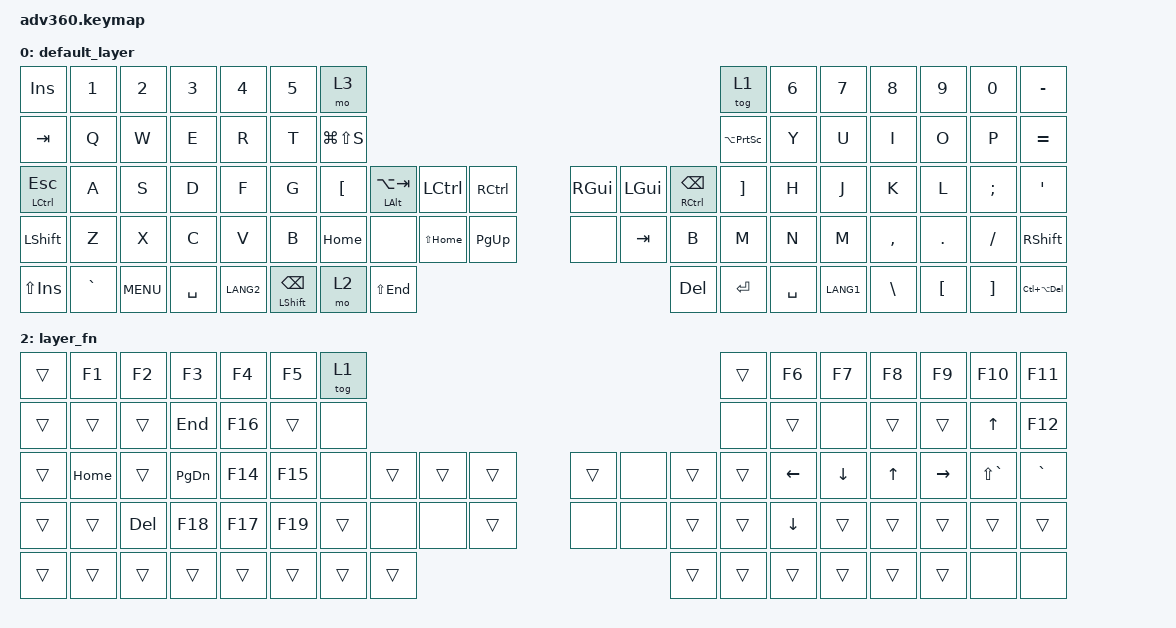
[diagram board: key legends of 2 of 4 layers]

/*
 * Copyright (c) 2020 The ZMK Contributors
 *
 * SPDX-License-Identifier: MIT
 */


/* THIS FILE WAS GENERATED!
 *
 * This file was generated automatically. You may or may not want to
 * edit it directly.
 */

#include <behaviors.dtsi>
#include <dt-bindings/zmk/keys.h>
#include <dt-bindings/zmk/bt.h>
#include <dt-bindings/zmk/rgb.h>
#include <dt-bindings/zmk/backlight.h>

/ {
  behaviors {
    #include "macros.dtsi"

    hm: homerow_mods {
        compatible = "zmk,behavior-hold-tap";
        label = "HOMEROW_MODS";
        #binding-cells = <2>;
        tapping-term-ms = <200>;
        quick_tap_ms = <175>;
        flavor = "tap-preferred";
        bindings = <&kp>, <&kp>;
    };
  };

    keymap {
        compatible = "zmk,keymap";


        default_layer {
            bindings = <
     &kp INSERT     &kp N1      &kp N2     &kp N3     &kp N4  &kp N5                          &mo 3                                                                                                  &tog 1  &kp N6     &kp N7         &kp N8    &kp N9    &kp N0        &kp MINUS
        &kp TAB      &kp Q       &kp W      &kp E      &kp R   &kp T                  &kp LG(LS(S))                                                                                     &kp LA(PRINTSCREEN)   &kp Y      &kp U          &kp I     &kp O     &kp P        &kp EQUAL
  &mt LCTRL ESC      &kp A       &kp S      &kp D      &kp F   &kp G                       &kp LBKT  &mt LEFT_ALT LA(TAB)     &kp LCTRL  &kp RCTRL  &kp RGUI  &kp LGUI  &mt RCTRL BSPC             &kp RBKT   &kp H      &kp J          &kp K     &kp L  &kp SEMI          &kp SQT
      &kp LSHFT      &kp Z       &kp X      &kp C      &kp V   &kp B                       &kp HOME                 &none  &kp LS(HOME)  &kp PG_UP     &none   &kp TAB           &kp B                &kp M   &kp N      &kp M      &kp COMMA   &kp DOT  &kp FSLH        &kp RSHFT
 &kp LS(INSERT)  &kp GRAVE  &kp C_MENU  &kp SPACE  &kp LANG2                    &mt LEFT_SHIFT BSPC                 &mo 2   &kp LS(END)                        &kp DEL       &kp ENTER            &kp SPACE          &kp LANG1  &kp BACKSLASH  &kp LBKT  &kp RBKT  &kp LC(LA(DEL))
            >;
        };

        layer_keypad {
            bindings = <
 &kp EQUAL    &kp N1     &kp N2    &kp N3   &kp N4  &kp N5              &trans                                                                     &mo 3     &kp N6  &kp KP_NUM  &kp KP_EQUAL  &kp KP_DIVIDE  &kp KP_MULTIPLY  &kp MINUS
   &kp TAB     &kp Q      &kp W     &kp E    &kp R   &kp T               &none                                                                     &none      &kp Y   &kp KP_N7     &kp KP_N8      &kp KP_N9     &kp KP_MINUS   &kp BSLH
   &kp ESC     &kp A      &kp S     &kp D    &kp F   &kp G               &none  &kp LCTRL   &kp LALT   &kp LGUI  &kp RCTRL      &none   &kp H  &kp KP_N4  &kp KP_N5   &kp KP_N6   &kp KP_PLUS        &kp SQT        &kp LSHFT      &kp Z
     &kp X     &kp C      &kp V     &kp B    &none   &none            &kp HOME      &none      &none  &kp PG_UP      &none      &none   &kp N  &kp KP_N1  &kp KP_N2   &kp KP_N3  &kp KP_ENTER      &kp RSHFT            &mo 2  &kp GRAVE
  &kp CAPS  &kp LEFT  &kp RIGHT  &kp BSPC  &kp DEL                     &kp END  &kp PG_DN  &kp ENTER                        &kp KP_N0  &kp UP   &kp DOWN             &kp KP_DOT      &kp RBKT          &mo 2
            >;
        };

        layer_fn {
            bindings = <
 &trans    &kp F1   &kp F2     &kp F3   &kp F4   &kp F5            &tog 1                                                  &trans          &kp F6          &kp F7        &kp F8           &kp F9        &kp F10    &kp F11
 &trans    &trans   &trans    &kp END  &kp F16   &trans             &none                                                   &none          &trans           &none        &trans           &trans   &kp UP_ARROW    &kp F12
 &trans  &kp HOME   &trans  &kp PG_DN  &kp F14  &kp F15             &none  &trans  &trans  &trans  &trans   &none  &trans  &trans  &kp LEFT_ARROW  &kp DOWN_ARROW  &kp UP_ARROW  &kp RIGHT_ARROW  &kp LS(GRAVE)  &kp GRAVE
 &trans    &trans  &kp DEL    &kp F18  &kp F17  &kp F19            &trans   &none   &none  &trans   &none   &none  &trans  &trans  &kp DOWN_ARROW          &trans        &trans           &trans         &trans     &trans
 &trans    &trans   &trans     &trans   &trans                     &trans  &trans  &trans                  &trans  &trans  &trans                          &trans        &trans           &trans          &none      &none
            >;
        };

        layer_mod {
            bindings = <
  &none  &bt BT_SEL 0  &bt BT_SEL 1     &bt BT_SEL 2  &bt BT_SEL 3  &bt BT_SEL 4                             &none                                                                                           &trans  &bt BT_SEL 0  &bt BT_SEL 1  &bt BT_SEL 2  &bt BT_SEL 3  &bt BT_SEL 4   &none
  &none         &none         &none            &none         &none         &none                       &bootloader                                                                                      &bootloader         &none         &none         &none         &none         &none   &none
  &none         &none         &none            &none         &none         &none            &rgb_ug RGB_MEFS_CMD 5  &bt BT_CLR       &none  &bt BT_CLR  &bt BT_CLR  &rgb_ug RGB_MEFS_CMD 5       &none        &none         &none         &none         &none         &none         &none   &none
  &none         &none         &none            &none         &none         &none                             &none       &none       &none       &none       &none                   &none       &none        &none         &none         &none         &none         &none         &none   &none
  &none    &bl BL_INC    &bl BL_DEC  &rgb_ug RGB_TOG    &bl BL_TOG                                           &none       &none  &bl BL_TOG                                 &rgb_ug RGB_TOG  &bl BL_INC   &bl BL_DEC                       &none         &none         &none
            >;
        };

    };
};
